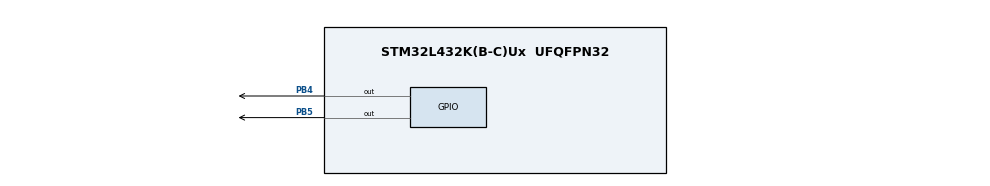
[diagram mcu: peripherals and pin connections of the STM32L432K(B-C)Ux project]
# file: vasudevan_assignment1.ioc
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Mcu.Family=STM32L4
Mcu.Name=STM32L432K(B-C)Ux
Mcu.Package=UFQFPN32
NVIC.PriorityGroup=NVIC_PRIORITYGROUP_4
PB4\ (NJTRST).Signal=GPIO_Output
PB5.Signal=GPIO_Output
ProjectManager.HeapSize=0x200
ProjectManager.StackSize=0x400
ProjectManager.TargetToolchain=STM32CubeIDE
RCC.HSE_VALUE=8000000
RCC.HSI48_VALUE=48000000
RCC.HSI_VALUE=16000000
RCC.LSE_VALUE=32768
RCC.MSI_VALUE=4000000
RCC.VCOOutputFreq_Value=32000000
board=custom

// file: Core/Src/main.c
/* USER CODE BEGIN Header */
/**
  ******************************************************************************
  * FILE           : main.c
  * PROJECT        : vasudevan_assignment
  * PROGRAMMER     : Pranav Manakkulamparambil Vasudevan
  * FIRST VERSION  : 2020-02-11
  * DESCRIPTION    : Code for embedded systems that writes the initial of any
  *                  name(hard coded) on the RGB led in international morse code.
  *                  first name initial displays on red led which is excited
  *                  by PB4 and last name initial is displays on green led which
  *                  is excited by PB5.
  ******************************************************************************
  * @attention
  *
  * <h2><center>&copy; Copyright (c) 2020 STMicroelectronics.
  * All rights reserved.</center></h2>
  *
  * This software component is licensed by ST under BSD 3-Clause license,
  * the "License"; You may not use this file except in compliance with the
  * License. You may obtain a copy of the License at:
  *                        opensource.org/licenses/BSD-3-Clause
  *
  ******************************************************************************
  */
/* USER CODE END Header */

#include "main.h"

void SystemClock_Config(void);
static void MX_GPIO_Init(void);

/* USER CODE BEGIN 0 */
//time delay constants
int dotTime   = 500; //the length of dot in Morse code
int dashTime  = 1500;//the length of dash in Morse code
int partSpace = 500;//The space between parts(dash and dot) of the same letter
int lettSpace = 1500;//The space between tow letters
int iniSpace  = 2500;//The space between two consecutive initials
//function declarations

void fdotCode();
void fdashCode();
void fspaceCode();
void ldotCode();

void ldashCode();

void lspaceCode();

char nameExtract(char fName[50], char lName[50]);//function to extract the initial from the first name and last name

void fgenerateMorse(char fInitial);

void lgenerateMorse(char lInitial);
/* USER CODE END 0 */

int main(void)
{

  /* MCU Configuration--------------------------------------------------------*/

  /* Reset of all peripherals, Initializes the Flash interface and the Systick. */
  HAL_Init();

  /* Configure the system clock */
  SystemClock_Config();

  /* Initialize all configured peripherals */
  MX_GPIO_Init();

  /* Infinite loop */
  while (1)
  {

    /* USER CODE BEGIN 3 */
	  nameExtract("pranav","vasudevan");//The function call to extract initials from first name and last name.

  }
  /* USER CODE END 3 */
}

void SystemClock_Config(void)
{
  RCC_OscInitTypeDef RCC_OscInitStruct = {0};
  RCC_ClkInitTypeDef RCC_ClkInitStruct = {0};

  /** Initializes the CPU, AHB and APB busses clocks
  */
  RCC_OscInitStruct.OscillatorType = RCC_OSCILLATORTYPE_MSI;
  RCC_OscInitStruct.MSIState = RCC_MSI_ON;
  RCC_OscInitStruct.MSICalibrationValue = 0;
  RCC_OscInitStruct.MSIClockRange = RCC_MSIRANGE_6;
  RCC_OscInitStruct.PLL.PLLState = RCC_PLL_NONE;
  if (HAL_RCC_OscConfig(&RCC_OscInitStruct) != HAL_OK)
  {
    Error_Handler();
  }
  /** Initializes the CPU, AHB and APB busses clocks
  */
  RCC_ClkInitStruct.ClockType = RCC_CLOCKTYPE_HCLK|RCC_CLOCKTYPE_SYSCLK
                              |RCC_CLOCKTYPE_PCLK1|RCC_CLOCKTYPE_PCLK2;
  RCC_ClkInitStruct.SYSCLKSource = RCC_SYSCLKSOURCE_MSI;
  RCC_ClkInitStruct.AHBCLKDivider = RCC_SYSCLK_DIV1;
  RCC_ClkInitStruct.APB1CLKDivider = RCC_HCLK_DIV1;
  RCC_ClkInitStruct.APB2CLKDivider = RCC_HCLK_DIV1;

  if (HAL_RCC_ClockConfig(&RCC_ClkInitStruct, FLASH_LATENCY_0) != HAL_OK)
  {
    Error_Handler();
  }
  /** Configure the main internal regulator output voltage
  */
  if (HAL_PWREx_ControlVoltageScaling(PWR_REGULATOR_VOLTAGE_SCALE1) != HAL_OK)
  {
    Error_Handler();
  }
}

static void MX_GPIO_Init(void)
{
  GPIO_InitTypeDef GPIO_InitStruct = {0};

  /* GPIO Ports Clock Enable */
  __HAL_RCC_GPIOB_CLK_ENABLE();

  /*Configure GPIO pin Output Level */
  HAL_GPIO_WritePin(GPIOB, GPIO_PIN_4|GPIO_PIN_5, GPIO_PIN_RESET);

  /*Configure GPIO pins : PB4 PB5 */
  GPIO_InitStruct.Pin = GPIO_PIN_4|GPIO_PIN_5;
  GPIO_InitStruct.Mode = GPIO_MODE_OUTPUT_PP;
  GPIO_InitStruct.Pull = GPIO_NOPULL;
  GPIO_InitStruct.Speed = GPIO_SPEED_FREQ_LOW;
  HAL_GPIO_Init(GPIOB, &GPIO_InitStruct);

}

/* USER CODE BEGIN 4 */
/*FUNCTION      : nameExtract
 * DESCRIPTION  :function to extract the initial from the first name and last name and
 *               doesn't return any values
 * PARAMETERS   :char fName : first name
 *               char lName : last name
 */
char nameExtract(char fName[50], char lName[50])
{
	char firstInitial = fName[0];//extracting the initial of first name
	char lastInitial = lName[0];//extracting the initial of last name
	fgenerateMorse(firstInitial);//function call to generate morse code for first initial
	HAL_Delay(lettSpace);//delay between initials
	lgenerateMorse(lastInitial);//function call to generate morse code for last initial
	HAL_Delay(iniSpace);//delay between Consecutive initials

}
/*FUNCTION      : fdotCode
 * DESCRIPTION  :function to generate a dot in the Morse code for first initial with no
 *               parameters and function doesn't return any values
 */
void fdotCode()
{
	HAL_GPIO_WritePin(GPIOB, GPIO_PIN_4, SET);
	HAL_Delay(dotTime);
}
/*FUNCTION      : fdashCode
 * DESCRIPTION  :function to generate a dash in the Morse code for first initial with no
 *               parameters and function doesn't return any values
 */
void fdashCode()
{
	HAL_GPIO_WritePin(GPIOB, GPIO_PIN_4, SET);
    HAL_Delay(dashTime);
}
/*FUNCTION      : fspaceCode
 * DESCRIPTION  :function to generate the gap between dot and dash for first initial with no
 *               parameters and function doesn't return any values
 */
void fspaceCode()
{
	HAL_GPIO_WritePin(GPIOB, GPIO_PIN_4, RESET);
    HAL_Delay(partSpace);
}
/*FUNCTION      : ldotCode
 * DESCRIPTION  :function to generate a dot in the Morse code for last initial with no
 *               parameters and function doesn't return any values
 */
void ldotCode()
{
	HAL_GPIO_WritePin(GPIOB, GPIO_PIN_5, SET);
	HAL_Delay(dotTime);
}
/*FUNCTION      : ldashCode
 * DESCRIPTION  :function to generate a dash in the Morse code for last initial with no
 *               parameters and function doesn't return any values
 */
void ldashCode()
{
	HAL_GPIO_WritePin(GPIOB, GPIO_PIN_5, SET);
    HAL_Delay(dashTime);
}
/*FUNCTION      : lspaceCode
 * DESCRIPTION  :function to generate the gap between dot and dash for last initial with no
 *               parameters and function doesn't return any values
 */
void lspaceCode()
{
	HAL_GPIO_WritePin(GPIOB, GPIO_PIN_5, RESET);
    HAL_Delay(partSpace);
}
/*FUNCTION      : fgenerateMorse
 * DESCRIPTION  :function to generate Morse code for the first name initial
 *               doesn't return any values
 * PARAMETERS   : fInitial : the first name initial
 */
void fgenerateMorse(char fInitial)
{
switch (fInitial)
{
         case 'a':
             fdotCode();
	  		 fspaceCode();
	  		 fdashCode();
	  		 fspaceCode();
	  		 break;
	  	 case 'b':
	  		 fdashCode();
	         fspaceCode();
	         fdotCode();
	         fspaceCode();
	         fdotCode();
             fspaceCode();
             fdotCode();
             fspaceCode();
            break;
	  	 case 'c':
	  		 fdashCode();
	  		 fspaceCode();
	  		 fdotCode();
	  		 fspaceCode();
	  		 fdashCode();
	  		 fspaceCode();
	  		 fdotCode();
	  		 fspaceCode();
	  		 break;
	  	 case 'd':
	  		 fdashCode();
	  		 fspaceCode();
	  		 fdotCode();
	  		 fspaceCode();
	  		 fdotCode();
	  		 fspaceCode();
	  		 break;
	  	 case 'e':
	  		 fdotCode();
	  		 fspaceCode();
	  		 break;
	  	 case 'f':
	  		 fdotCode();
	  		 fspaceCode();
	  		 fdotCode();
	  		 fspaceCode();
	  		 fdashCode();
	  		 fspaceCode();
	  		 fdotCode();
	  		 fspaceCode();
	  		 break;
	  	 case 'g':
	  		 fdashCode();
	  		 fspaceCode();
	  		 fdashCode();
	  		 fspaceCode();
	  		 fdotCode();
	  		 fspaceCode();
	  		 break;
	  	 case 'h':
	  		 fdotCode();
	  		 fspaceCode();
	  		 fdotCode();
	  		 fspaceCode();
	  		 fdotCode();
	  		 fspaceCode();
	  		 fdotCode();
	  		 fspaceCode();
	  		 break;
	  	 case 'i':
	  		 fdotCode();
	  		 fspaceCode();
	  		 fdotCode();
	  		 fspaceCode();
	  		 break;
	  	 case 'j':
	  		 fdotCode();
	  		 fspaceCode();
	  		 fdashCode();
	  		 fspaceCode();
	  		 fdashCode();
	  		 fspaceCode();
	  		 fdashCode();
	  		 fspaceCode();
	  		 break;
	  	 case 'k':
	  		 fdashCode();
	  		 fspaceCode();
	  		 fdotCode();
	  		 fspaceCode();
	  		 fdashCode();
	  		 fspaceCode();
	  		 break;
	  	 case 'l':
	  	     fdotCode();
	  	     fspaceCode();
	  		 fdashCode();
	  		 fspaceCode();
	  	     fdotCode();
	  	     fspaceCode();
	  	     fdotCode();
	  	     fspaceCode();
	  	     break;
	  	 case 'm':
	  		 fdashCode();
	  		 fspaceCode();
	  		 fdashCode();
	  		 fspaceCode();
	  		 break;
	  	 case 'n':
	  		 fdashCode();
	  		 fspaceCode();
	  	     fdotCode();
	  	     fspaceCode();
	  	     break;
	  	 case 'o':
	  		 fdashCode();
	  		 fspaceCode();
	  		 fdashCode();
	  		 fspaceCode();
	  		 fdashCode();
	  		 fspaceCode();
	  		 break;
	  	 case 'p':
	  	     fdotCode();
	  	     fspaceCode();
	  		 fdashCode();
	  		 fspaceCode();
	  		 fdashCode();
	  		 fspaceCode();
	  	     fdotCode();
	  	     fspaceCode();
	  	     break;
	  	 case 'q':
	  		 fdashCode();
	  		 fspaceCode();
	  		 fdashCode();
	  		 fspaceCode();
	  	     fdotCode();
	  	     fspaceCode();
	  		 fdashCode();
	  		 fspaceCode();
	  		 break;
	  	 case 'r':
	  	     fdotCode();
	  	     fspaceCode();
	  		 fdashCode();
	  		 fspaceCode();
	  	     fdotCode();
	  	     fspaceCode();
	  		 break;
	  	 case 's':
	  	     fdotCode();
	  	     fspaceCode();
	  	     fdotCode();
	  	     fspaceCode();
	  	     fdotCode();
	  	     fspaceCode();
	  	     break;
	  	 case 't':
	  		 fdashCode();
	  		 fspaceCode();
	  		 break;
	  	 case 'u':
	  	     fdotCode();
	  	     fspaceCode();
	  	     fdotCode();
	  	     fspaceCode();
	  		 fdashCode();
	  		 fspaceCode();
	  		 break;
	  	 case 'v':
	  	     fdotCode();
	  	     fspaceCode();
	  	     fdotCode();
	  	     fspaceCode();
	  	     fdotCode();
	  	     fspaceCode();
	  		 fdashCode();
	  		 fspaceCode();
	  		 break;
	  	 case 'w':
	  	     fdotCode();
	  	     fspaceCode();
	  		 fdashCode();
	  		 fspaceCode();
	  		 fdashCode();
	  		 fspaceCode();
	  		 break;
	  	 case 'x':
	  		 fdashCode();
	  		 fspaceCode();
	  	     fdotCode();
	  	     fspaceCode();
	  	     fdotCode();
	  	     fspaceCode();
	  		 fdashCode();
	  		 fspaceCode();
	  		 break;
	  	 case 'y':
	  		 fdashCode();
	  		 fspaceCode();
	  	     fdotCode();
	  	     fspaceCode();
	  		 fdashCode();
	  		 fspaceCode();
	  		 fdashCode();
	  		 fspaceCode();
	  		 break;
	  	 case 'z':
	  		 fdashCode();
	  		 fspaceCode();
	  		 fdashCode();
	  		 fspaceCode();
	  	     fdotCode();
	  	     fspaceCode();
	  	     fdotCode();
	  	     fspaceCode();
	  	     break;
	  	}
	  }
/*FUNCTION      : lgenerateMorse
 * DESCRIPTION  :function to generate Morse code for the last name initial
 *               doesn't return any values
 * PARAMETERS   :lInitial: the last name initial
 */
void lgenerateMorse(char lInitial)
{
  switch (lInitial)
  {
	  	 case 'a':
	  		 ldotCode();
	  		 lspaceCode();
	  	 	 ldashCode();
	  		 lspaceCode();
	  		 break;
	  	 case 'b':
	  		 ldashCode();
	           lspaceCode();
	           ldotCode();
	           lspaceCode();
	           ldotCode();
	           lspaceCode();
	           ldotCode();
	           lspaceCode();
	           break;
	  	 case 'c':
	  		 ldashCode();
	  		 lspaceCode();
	  		 ldotCode();
	  		 lspaceCode();
	  		 ldashCode();
	  		 lspaceCode();
	  		 ldotCode();
	  		 lspaceCode();
	  		 break;
	  	 case 'd':
	  		 ldashCode();
	  		 lspaceCode();
	  		 ldotCode();
	  		 lspaceCode();
	  		 ldotCode();
	  		 lspaceCode();
	  		 break;
	  	 case 'e':
	  		 ldotCode();
	  		 lspaceCode();
	  		 break;
	  	 case 'f':
	  		 ldotCode();
	  		 lspaceCode();
	  		 ldotCode();
	  		 lspaceCode();
	  		 ldashCode();
	  		 lspaceCode();
	  		 ldotCode();
	  		 lspaceCode();
	  		 break;
	  	 case 'g':
	  		 ldashCode();
	  		 lspaceCode();
	  		 ldashCode();
	  		 lspaceCode();
	  		 ldotCode();
	  		 lspaceCode();
	  		 break;
	  	 case 'h':
	  		 ldotCode();
	  		 lspaceCode();
	  		 ldotCode();
	  		 lspaceCode();
	  		 ldotCode();
	  		 lspaceCode();
	  		 ldotCode();
	  		 lspaceCode();
	  		 break;
	  	 case 'i':
	  		 ldotCode();
	  		 lspaceCode();
	  		 ldotCode();
	  		 lspaceCode();
	  		 break;
	  	 case 'j':
	  		 ldotCode();
	  		 lspaceCode();
	  		 ldashCode();
	  		 lspaceCode();
	  		 ldashCode();
	  		 lspaceCode();
	  		 ldashCode();
	  		 lspaceCode();
	  		 break;
	  	 case 'k':
	  		 ldashCode();
	  		 lspaceCode();
	  		 ldotCode();
	  		 lspaceCode();
	  		 ldashCode();
	  		 lspaceCode();
	  		 break;
	  	 case 'l':
	  	     ldotCode();
	  	     lspaceCode();
	  		 ldashCode();
	  		 lspaceCode();
	  	     ldotCode();
	  	     lspaceCode();
	  	     ldotCode();
	  	     lspaceCode();
	  	     break;
	  	 case 'm':
	  		 ldashCode();
	  		 lspaceCode();
	  		 ldashCode();
	  		 lspaceCode();
	  		 break;
	  	 case 'n':
	  		 ldashCode();
	  		 lspaceCode();
	  	     ldotCode();
	  	     lspaceCode();
	  	     break;
	  	 case 'o':
	  		 ldashCode();
	  		 lspaceCode();
	  		 ldashCode();
	  		 lspaceCode();
	  		 ldashCode();
	  		 lspaceCode();
	  		 break;
	  	 case 'p':
	  	     ldotCode();
	  	     lspaceCode();
	  		 ldashCode();
	  		 lspaceCode();
	  		 ldashCode();
	  		 lspaceCode();
	  	     ldotCode();
	  	     lspaceCode();
	  	     break;
	  	 case 'q':
	  		 ldashCode();
	  		 lspaceCode();
	  		 ldashCode();
	  		 lspaceCode();
	  	     ldotCode();
	  	     lspaceCode();
	  		 ldashCode();
	  		 lspaceCode();
	  		 break;
	  	 case 'r':
	  	     ldotCode();
	  	     lspaceCode();
	  		 ldashCode();
	  		 lspaceCode();
	  	     ldotCode();
	  	     lspaceCode();
	  		 break;
	  	 case 's':
	  	     ldotCode();
	  	     lspaceCode();
	  	     ldotCode();
	  	     lspaceCode();
	  	     ldotCode();
	  	     lspaceCode();
	  	     break;
	  	 case 't':
	  		 ldashCode();
	  		 lspaceCode();
	  		 break;
	  	 case 'u':
	  	     ldotCode();
	  	     lspaceCode();
	  	     ldotCode();
	  	     lspaceCode();
	  		 ldashCode();
	  		 lspaceCode();
	  		 break;
	  	 case 'v':
	  	     ldotCode();
	  	     lspaceCode();
	  	     ldotCode();
	  	     lspaceCode();
	  	     ldotCode();
	  	     lspaceCode();
	  		 ldashCode();
	  		 lspaceCode();
	  		 break;
	  	 case 'w':
	  	     ldotCode();
	  	     lspaceCode();
	  		 ldashCode();
	  		 lspaceCode();
	  		 ldashCode();
	  		 lspaceCode();
	  		 break;
	  	 case 'x':
	  		 ldashCode();
	  		 lspaceCode();
	  	     ldotCode();
	  	     lspaceCode();
	  	     ldotCode();
	  	     lspaceCode();
	  		 ldashCode();
	  		 lspaceCode();
	  		 break;
	  	 case 'y':
	  		 ldashCode();
	  		 lspaceCode();
	  	     ldotCode();
	  	     lspaceCode();
	  		 ldashCode();
	  		 lspaceCode();
	  		 ldashCode();
	  		 lspaceCode();
	  		 break;
	  	 case 'z':
	  		 ldashCode();
	  		 lspaceCode();
	  		 ldashCode();
	  		 lspaceCode();
	  	     ldotCode();
	  	     lspaceCode();
	  	     ldotCode();
	  	     lspaceCode();
	  	     break;
	  	}

	  }
/* USER CODE END 4 */

void Error_Handler(void)
{
}

/************************ (C) COPYRIGHT STMicroelectronics *****END OF FILE****/
